# STM32F301x8 register map
File version: 1.0
Registers are 32-bit, read-write, reset 0x0 unless marked. A register's access mark holds for its fields unless they carry their own. Offsets are from the block's base; [hi:lo] are bit positions; {n}, {i} and the like mark numbered series.

## IWDG — Independent WATCHDOG
Base 0x40003000
0x00 KR — IWDG Key register
  [15:0] KEY — Key value (write only, read 0000h)
0x04 PR — IWDG Prescaler register
  [2:0] PR — PR[2:0] (Prescaler divider)
0x08 RLR — IWDG Reload register
  [11:0] RL — Watchdog counter reload value
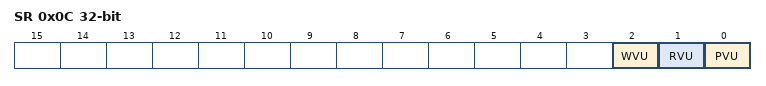
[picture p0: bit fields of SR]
0x0C SR — IWDG Status register
  [2] WVU — Watchdog counter window value update
  [1] RVU — Watchdog counter reload value update
  [0] PVU — Watchdog prescaler value update
0x10 WINR — IWDG Window register
  [11:0] WIN — Watchdog counter window value

## PWR — Power Control
Base 0x40007000
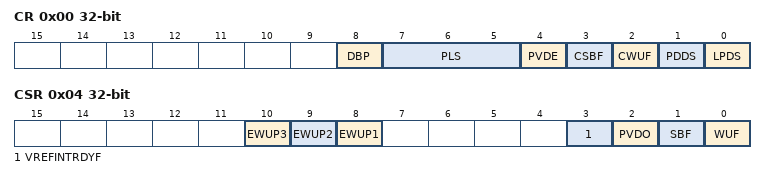
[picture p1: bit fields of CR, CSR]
0x00 CR — PWR power control register
  [8] DBP — Disable Backup Domain write protection
  [7:5] PLS — PLS[2:0] bits (PVD Level Selection)
    0=PVDLEVEL_0 (Voltage threshold detected by PVD 2.2 V); 1=PVDLEVEL_1 (Voltage threshold detected by PVD 2.3 V); 2=PVDLEVEL_2 (Voltage threshold detected by PVD 2.4 V); 3=PVDLEVEL_3 (Voltage threshold detected by PVD 2.5 V); 4=PVDLEVEL_4 (Voltage threshold detected by PVD 2.6 V); 5=PVDLEVEL_5 (Voltage threshold detected by PVD 2.7 V); 6=PVDLEVEL_6 (Voltage threshold detected by PVD 2.8 V); 7=PVDLEVEL_7 (Voltage threshold detected by PVD 2.9 V)
  [4] PVDE — Power Voltage Detector Enable
  [3] CSBF — Clear Standby Flag
  [2] CWUF — Clear Wakeup Flag
  [1] PDDS — Power Down Deepsleep
  [0] LPDS — Low-power Deepsleep
    0=MAIN (Voltage Regulator in main mode during deepsleep mode); 1=LOW_POWER (Voltage Regulator in low-power mode during deepsleep mode)
0x04 CSR — PWR power control/status register
  [10] EWUP3 — Enable WKUP pin 3
  [9] EWUP2 — Enable WKUP pin 2
  [8] EWUP1 — Enable WKUP pin 1
  [3] VREFINTRDYF — Internal voltage reference (VREFINT) ready flag
  [2] PVDO — PVD Output
  [1] SBF — Standby Flag
  [0] WUF — Wakeup Flag

## DAC — Digital to Analog Converter
Base 0x40007400
Same registers: DAC1 0x40007400 (alternate view of DAC)
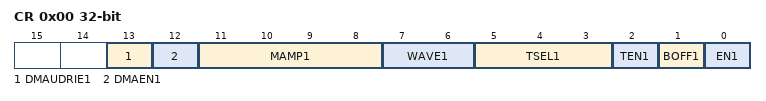
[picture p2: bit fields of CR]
0x00 CR — DAC control register
  [13] DMAUDRIE1 — DAC channel1 DMA underrun IT enable
  [12] DMAEN1 — DAC channel1 DMA enable
  [11:8] MAMP1 — MAMP1[3:0] (DAC channel1 Mask/Amplitude selector)
  [7:6] WAVE1 — WAVE1[1:0] (DAC channel1 noise/triangle wave generation enable)
  [5:3] TSEL1 — TSEL1[2:0] (DAC channel1 Trigger selection)
  [2] TEN1 — DAC channel1 Trigger enable
  [1] BOFF1 — DAC channel1 output buffer disable
  [0] EN1 — DAC channel1 enable
0x04 SWTRIGR — DAC software trigger register
  [0] SWTRIG1 — DAC channel1 software trigger
0x08 DHR12R1 — DAC channel1 12-bit right-aligned data holding register
  [11:0] DACC1DHR — DAC channel1 12-bit Right aligned data
0x0C DHR12L1 — DAC channel1 12-bit left aligned data holding register
  [15:4] DACC1DHR — DAC channel1 12-bit Left aligned data
0x10 DHR8R1 — DAC channel1 8-bit right aligned data holding register
  [7:0] DACC1DHR — DAC channel1 8-bit Right aligned data
0x20 DHR12RD — Dual DAC 12-bit right-aligned data holding register
  [11:0] DACC1DHR — DAC channel1 12-bit Right aligned data
0x24 DHR12LD — DUAL DAC 12-bit left aligned data holding register
  [15:4] DACC1DHR — DAC channel1 12-bit Left aligned data
0x28 DHR8RD — DUAL DAC 8-bit right aligned data holding register
  [7:0] DACC1DHR — DAC channel1 8-bit Right aligned data
0x2C DOR1 — DAC channel1 data output register
  [11:0] DACC1DOR — DAC channel1 data output
0x34 SR — DAC status register
  [13] DMAUDR1 — DAC channel1 DMA underrun flag

## SYSCFG — System configuration controller
Base 0x40010000
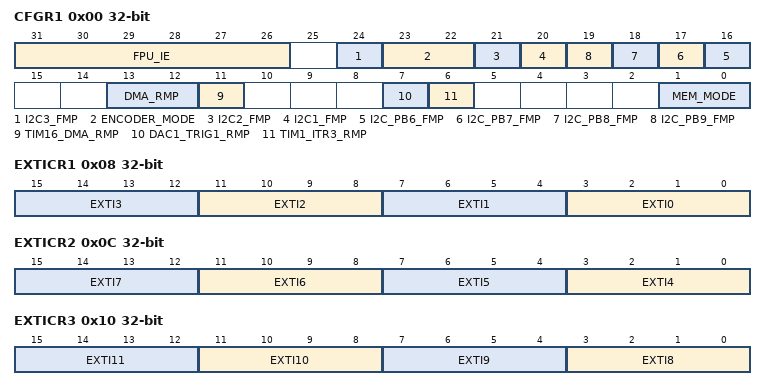
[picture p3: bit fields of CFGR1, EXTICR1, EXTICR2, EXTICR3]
0x00 CFGR1 — SYSCFG configuration register 1
  [31:26] FPU_IE — Floating Point Unit Interrupt Enable
  [24] I2C3_FMP — I2C3 Fast mode plus
  [23:22] ENCODER_MODE
  [21] I2C2_FMP — I2C2 Fast mode plus
  [20] I2C1_FMP — I2C1 Fast mode plus
  [n+10] I2C_PB{n}_FMP (n=6..9) — I2C PB{n} Fast mode plus
  [13:12] DMA_RMP — DMA remap mask
  [11] TIM16_DMA_RMP — Timer 16 DMA remap
  [7] DAC1_TRIG1_RMP — DAC1 Trigger1 remap
  [6] TIM1_ITR3_RMP — Timer 1 ITR3 selection
  [1:0] MEM_MODE — SYSCFG_Memory Remap Config
    0=FLASH; 1=SYSTEMFLASH; 3=SRAM
0x08 EXTICR1 — SYSCFG external interrupt configuration registers
  [4n+3:4n] EXTI{n} (n=0..3) — EXTI {n} configuration
0x0C EXTICR2 — SYSCFG external interrupt configuration registers
  [4n-13:4n-16] EXTI{n} (n=4..7) — EXTI {n} configuration
0x10 EXTICR3 — SYSCFG external interrupt configuration registers
  [4n-29:4n-32] EXTI{n} (n=8..11) — EXTI {n} configuration
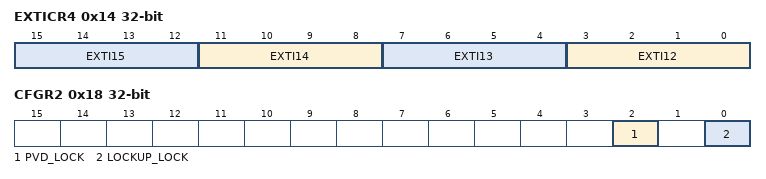
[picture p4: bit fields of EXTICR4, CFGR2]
0x14 EXTICR4 — SYSCFG external interrupt configuration registers
  [4n-45:4n-48] EXTI{n} (n=12..15) — EXTI {n} configuration
0x18 CFGR2 — SYSCFG configuration register 2
  [2] PVD_LOCK — Enables and locks the PVD connection with TIMx Break Input, as well as the PVDE and PLS[2:0] in the PWR_CR register
  [0] LOCKUP_LOCK — Enables and locks the LOCKUP (Hardfault) output of CortexM4 with Break Input of TIMx
